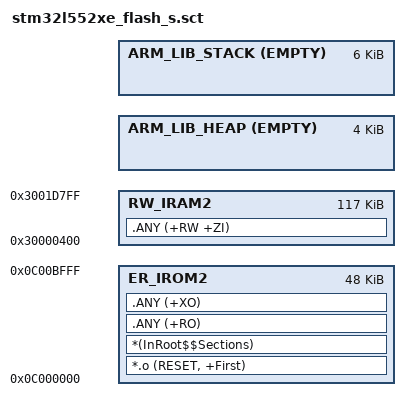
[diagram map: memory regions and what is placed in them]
; *************************************************************
; *** Scatter-Loading Description File generated by uVision ***
; *************************************************************

LR_IROM2 0x0C000000 0x0000C000  {    ; load region size_region
  ER_IROM2 0x0C000000 0x0000C000  {  ; load address = execution address
   *.o (RESET, +First)
   *(InRoot$$Sections)
   .ANY (+RO)
   .ANY (+XO)
  }
  RW_IRAM2 0x30000400 0x0001D400  {  ; RW data
   .ANY (+RW +ZI)
  }
  ARM_LIB_HEAP +0 EMPTY 0x1000  {    ; Heap region
  }
  ARM_LIB_STACK +0 EMPTY 0x1800  {   ; Stack region
  }
}
